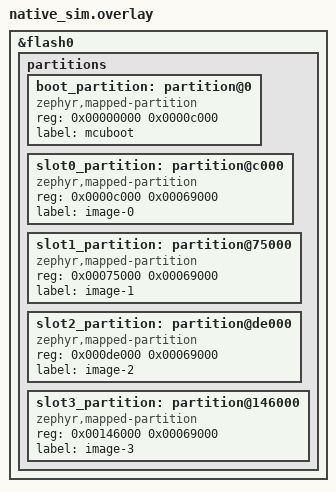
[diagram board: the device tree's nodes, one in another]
/*
 * Copyright (c) 2020 Nordic Semiconductor ASA
 *
 * SPDX-License-Identifier: Apache-2.0
 */

/delete-node/ &scratch_partition;
/delete-node/ &storage_partition;

&flash0 {
	partitions {
		ranges;
		#address-cells = <1>;
		#size-cells = <1>;

		boot_partition: partition@0 {
			compatible = "zephyr,mapped-partition";
			reg = <0x00000000 0x0000c000>;
			label = "mcuboot";
		};

		slot0_partition: partition@c000 {
			compatible = "zephyr,mapped-partition";
			reg = <0x0000c000 0x00069000>;
			label = "image-0";
		};

		slot1_partition: partition@75000 {
			compatible = "zephyr,mapped-partition";
			reg = <0x00075000 0x00069000>;
			label = "image-1";
		};

		slot2_partition: partition@de000 {
			compatible = "zephyr,mapped-partition";
			reg = <0x000de000 0x00069000>;
			label = "image-2";
		};

		slot3_partition: partition@146000 {
			compatible = "zephyr,mapped-partition";
			reg = <0x00146000 0x00069000>;
			label = "image-3";
		};
	};
};
